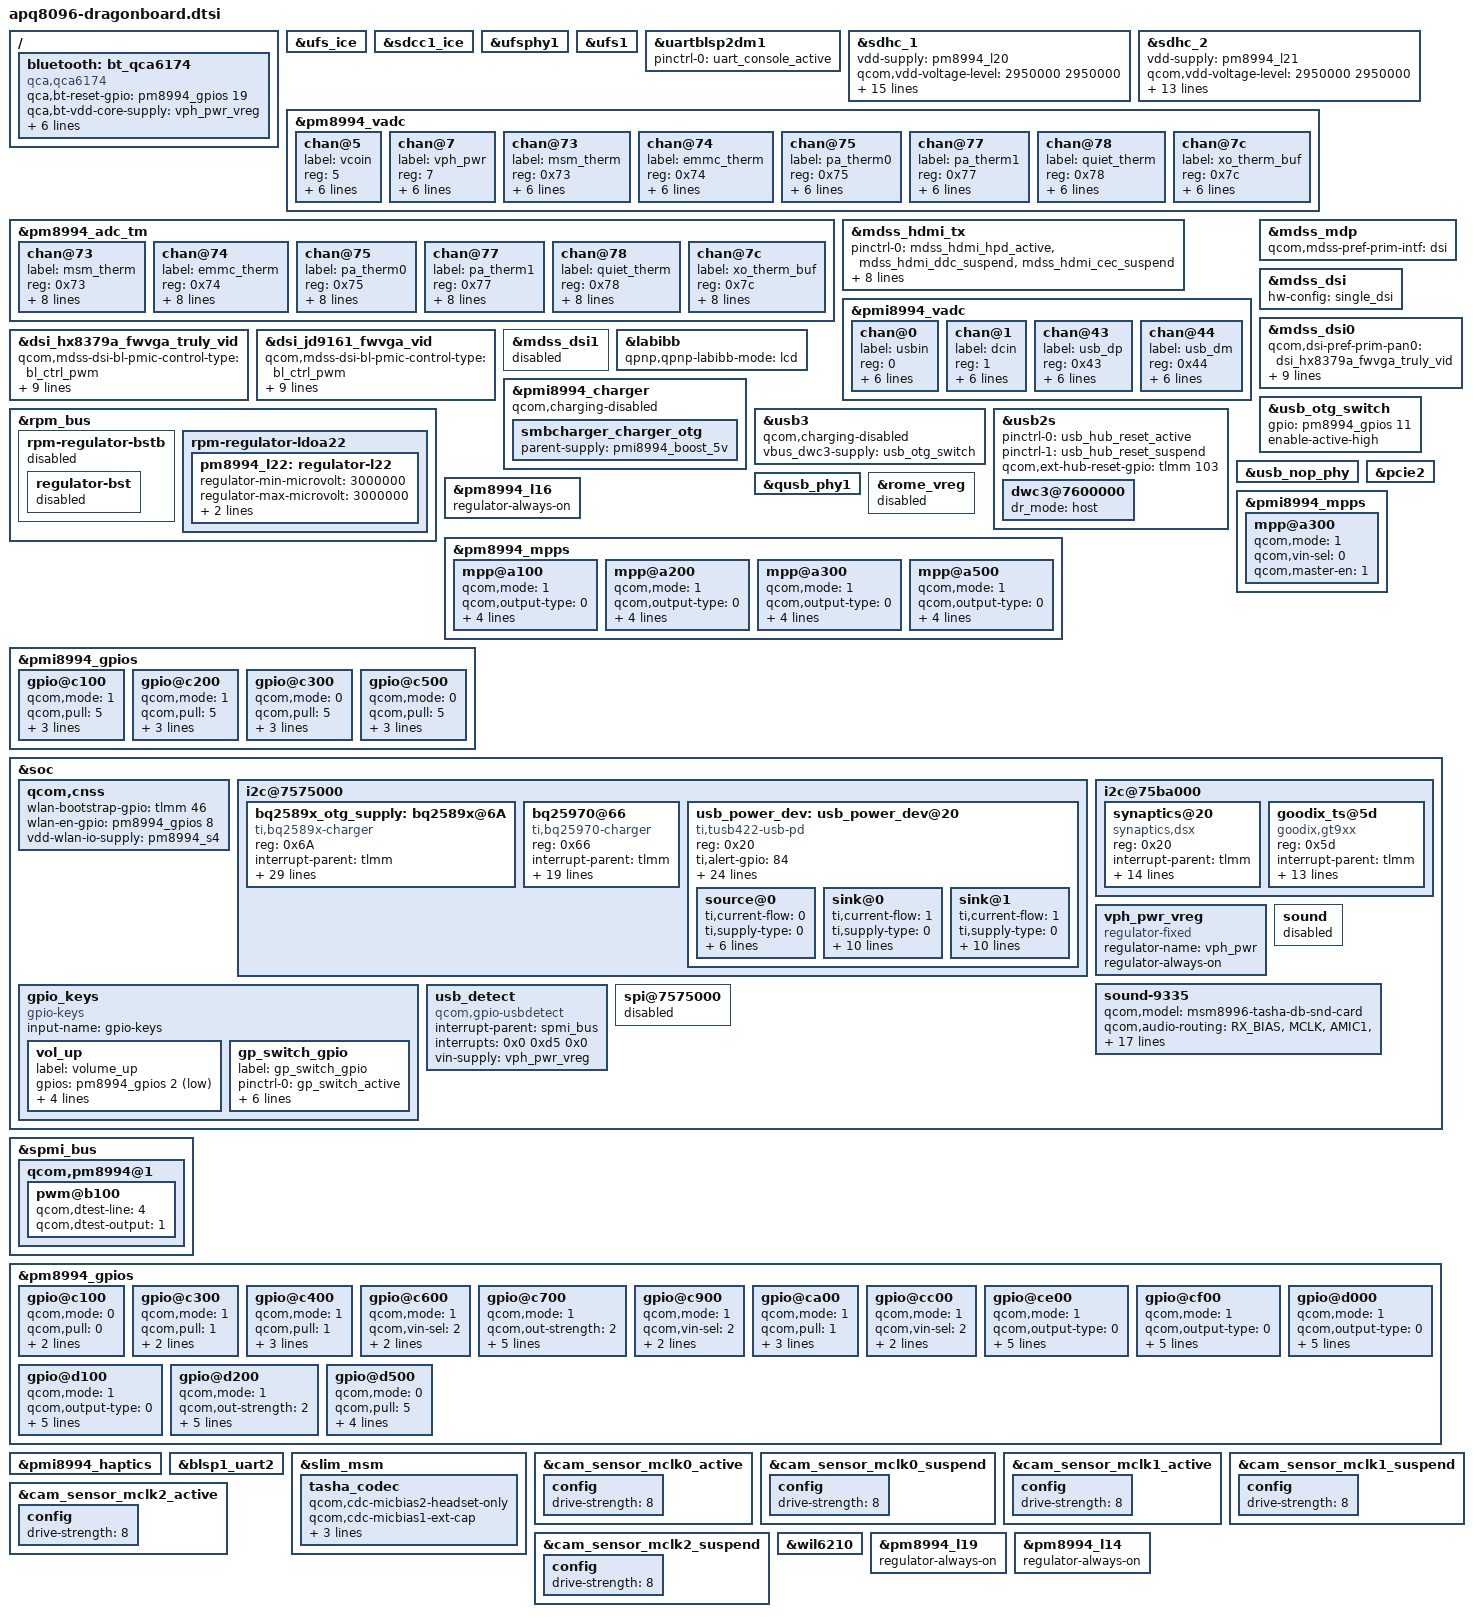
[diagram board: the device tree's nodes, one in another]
/* Copyright (c) 2015-2016, The Linux Foundation. All rights reserved.
 *
 * This program is free software; you can redistribute it and/or modify
 * it under the terms of the GNU General Public License version 2 and
 * only version 2 as published by the Free Software Foundation.
 *
 * This program is distributed in the hope that it will be useful,
 * but WITHOUT ANY WARRANTY; without even the implied warranty of
 * MERCHANTABILITY or FITNESS FOR A PARTICULAR PURPOSE.  See the
 * GNU General Public License for more details.
 */

#include "msm8996-pinctrl.dtsi"
#include "apq8096-camera-sensor-dragonboard.dtsi"

/ {
	bluetooth: bt_qca6174 {
		compatible = "qca,qca6174";
		qca,bt-reset-gpio = <&pm8994_gpios 19 0>; /* BT_EN */
		qca,bt-vdd-core-supply = <&vph_pwr_vreg>;
		qca,bt-vdd-pa-supply = <&vph_pwr_vreg>;
		qca,bt-vdd-io-supply = <&pm8994_s4>;
		qca,bt-vdd-xtal-supply = <&vph_pwr_vreg>;
		qca,bt-chip-pwd-voltage-level = <1300000 1300000>;
		qca,bt-vdd-io-voltage-level = <1800000 1800000>;
		qca,bt-vdd-xtal-voltage-level = <1800000 1800000>;
	};
};

&ufs_ice {
	status = "ok";
};

&sdcc1_ice {
	status = "ok";
};

&ufsphy1 {
	status = "ok";
};

&ufs1 {
	status = "ok";
};

&uartblsp2dm1 {
	status = "ok";
	pinctrl-names = "default";
	pinctrl-0 = <&uart_console_active>;
};

&sdhc_1 {
	vdd-supply = <&pm8994_l20>;
	qcom,vdd-voltage-level = <2950000 2950000>;
	qcom,vdd-current-level = <200 570000>;

	vdd-io-supply = <&pm8994_s4>;
	qcom,vdd-io-always-on;
	qcom,vdd-io-voltage-level = <1800000 1800000>;
	qcom,vdd-io-current-level = <110 325000>;

	pinctrl-names = "active", "sleep";
	pinctrl-0 = <&sdc1_clk_on &sdc1_cmd_on &sdc1_data_on &sdc1_rclk_on>;
	pinctrl-1 = <&sdc1_clk_off &sdc1_cmd_off &sdc1_data_off &sdc1_rclk_off>;

	qcom,clk-rates = <400000 20000000 25000000 50000000
				96000000 192000000 384000000>;
	qcom,ice-clk-rates = <300000000 150000000>;
	qcom,nonremovable;
	qcom,bus-speed-mode = "HS400_1p8v", "HS200_1p8v", "DDR_1p8v";

	status = "ok";
};

&sdhc_2 {
	vdd-supply = <&pm8994_l21>;
	qcom,vdd-voltage-level = <2950000 2950000>;
	qcom,vdd-current-level = <200 800000>;

	vdd-io-supply = <&pm8994_l13>;
	qcom,vdd-io-voltage-level = <1800000 2950000>;
	qcom,vdd-io-current-level = <200 22000>;

	pinctrl-names = "active", "sleep";
	pinctrl-0 = <&sdc2_clk_on  &sdc2_cmd_on &sdc2_data_on &sdc2_cd_on>;
	pinctrl-1 = <&sdc2_clk_off &sdc2_cmd_off &sdc2_data_off &sdc2_cd_off>;

	qcom,clk-rates = <400000 20000000 25000000 50000000
				100000000 200000000>;
	qcom,bus-speed-mode = "SDR12", "SDR25", "SDR50", "DDR50", "SDR104";

	cd-gpios = <&tlmm 95 0x1>;

	status = "ok";
};

&pm8994_vadc {
	chan@5 {
		label = "vcoin";
		reg = <5>;
		qcom,decimation = <0>;
		qcom,pre-div-channel-scaling = <1>;
		qcom,calibration-type = "absolute";
		qcom,scale-function = <0>;
		qcom,hw-settle-time = <0>;
		qcom,fast-avg-setup = <0>;
	};

	chan@7 {
		label = "vph_pwr";
		reg = <7>;
		qcom,decimation = <0>;
		qcom,pre-div-channel-scaling = <1>;
		qcom,calibration-type = "absolute";
		qcom,scale-function = <0>;
		qcom,hw-settle-time = <0>;
		qcom,fast-avg-setup = <0>;
	};

	chan@73 {
		label = "msm_therm";
		reg = <0x73>;
		qcom,decimation = <0>;
		qcom,pre-div-channel-scaling = <0>;
		qcom,calibration-type = "ratiometric";
		qcom,scale-function = <2>;
		qcom,hw-settle-time = <2>;
		qcom,fast-avg-setup = <0>;
	};

	chan@74 {
		label = "emmc_therm";
		reg = <0x74>;
		qcom,decimation = <0>;
		qcom,pre-div-channel-scaling = <0>;
		qcom,calibration-type = "ratiometric";
		qcom,scale-function = <2>;
		qcom,hw-settle-time = <2>;
		qcom,fast-avg-setup = <0>;
	};

	chan@75 {
		label = "pa_therm0";
		reg = <0x75>;
		qcom,decimation = <0>;
		qcom,pre-div-channel-scaling = <0>;
		qcom,calibration-type = "ratiometric";
		qcom,scale-function = <2>;
		qcom,hw-settle-time = <2>;
		qcom,fast-avg-setup = <0>;
	};

	chan@77 {
		label = "pa_therm1";
		reg = <0x77>;
		qcom,decimation = <0>;
		qcom,pre-div-channel-scaling = <0>;
		qcom,calibration-type = "ratiometric";
		qcom,scale-function = <2>;
		qcom,hw-settle-time = <2>;
		qcom,fast-avg-setup = <0>;
	};

	chan@78 {
		label = "quiet_therm";
		reg = <0x78>;
		qcom,decimation = <0>;
		qcom,pre-div-channel-scaling = <0>;
		qcom,calibration-type = "ratiometric";
		qcom,scale-function = <2>;
		qcom,hw-settle-time = <2>;
		qcom,fast-avg-setup = <0>;
	};

	chan@7c {
		label = "xo_therm_buf";
		reg = <0x7c>;
		qcom,decimation = <0>;
		qcom,pre-div-channel-scaling = <0>;
		qcom,calibration-type = "ratiometric";
		qcom,scale-function = <4>;
		qcom,hw-settle-time = <2>;
		qcom,fast-avg-setup = <0>;
	};
};

&pm8994_adc_tm {
	chan@73 {
		label = "msm_therm";
		reg = <0x73>;
		qcom,decimation = <0>;
		qcom,pre-div-channel-scaling = <0>;
		qcom,calibration-type = "ratiometric";
		qcom,scale-function = <2>;
		qcom,hw-settle-time = <2>;
		qcom,fast-avg-setup = <0>;
		qcom,btm-channel-number = <0x48>;
		qcom,thermal-node;
	};

	chan@74 {
		label = "emmc_therm";
		reg = <0x74>;
		qcom,decimation = <0>;
		qcom,pre-div-channel-scaling = <0>;
		qcom,calibration-type = "ratiometric";
		qcom,scale-function = <2>;
		qcom,hw-settle-time = <2>;
		qcom,fast-avg-setup = <0>;
		qcom,btm-channel-number = <0x68>;
		qcom,thermal-node;
	};

	chan@75 {
		label = "pa_therm0";
		reg = <0x75>;
		qcom,decimation = <0>;
		qcom,pre-div-channel-scaling = <0>;
		qcom,calibration-type = "ratiometric";
		qcom,scale-function = <2>;
		qcom,hw-settle-time = <2>;
		qcom,fast-avg-setup = <0>;
		qcom,btm-channel-number = <0x70>;
		qcom,thermal-node;
	};

	chan@77 {
		label = "pa_therm1";
		reg = <0x77>;
		qcom,decimation = <0>;
		qcom,pre-div-channel-scaling = <0>;
		qcom,calibration-type = "ratiometric";
		qcom,scale-function = <2>;
		qcom,hw-settle-time = <2>;
		qcom,fast-avg-setup = <0>;
		qcom,btm-channel-number = <0x78>;
		qcom,thermal-node;
	};

	chan@78 {
		label = "quiet_therm";
		reg = <0x78>;
		qcom,decimation = <0>;
		qcom,pre-div-channel-scaling = <0>;
		qcom,calibration-type = "ratiometric";
		qcom,scale-function = <2>;
		qcom,hw-settle-time = <2>;
		qcom,fast-avg-setup = <0>;
		qcom,btm-channel-number = <0x80>;
		qcom,thermal-node;
	};

	chan@7c {
		label = "xo_therm_buf";
		reg = <0x7c>;
		qcom,decimation = <0>;
		qcom,pre-div-channel-scaling = <0>;
		qcom,calibration-type = "ratiometric";
		qcom,scale-function = <4>;
		qcom,hw-settle-time = <2>;
		qcom,fast-avg-setup = <0>;
		qcom,btm-channel-number = <0x88>;
		qcom,thermal-node;
	};
};

&mdss_hdmi_tx {
	pinctrl-names = "hdmi_hpd_active", "hdmi_ddc_active", "hdmi_cec_active",
				"hdmi_active", "hdmi_sleep";
	pinctrl-0 = <&mdss_hdmi_hpd_active &mdss_hdmi_ddc_suspend
						&mdss_hdmi_cec_suspend>;
	pinctrl-1 = <&mdss_hdmi_hpd_active &mdss_hdmi_ddc_active
						&mdss_hdmi_cec_suspend>;
	pinctrl-2 = <&mdss_hdmi_hpd_active &mdss_hdmi_cec_active
						&mdss_hdmi_ddc_suspend>;
	pinctrl-3 = <&mdss_hdmi_hpd_active &mdss_hdmi_ddc_active
						&mdss_hdmi_cec_active>;
	pinctrl-4 = <&mdss_hdmi_hpd_suspend &mdss_hdmi_ddc_suspend
						&mdss_hdmi_cec_suspend>;
};

&pmi8994_vadc {
	chan@0 {
		label = "usbin";
		reg = <0>;
		qcom,decimation = <0>;
		qcom,pre-div-channel-scaling = <4>;
		qcom,calibration-type = "absolute";
		qcom,scale-function = <0>;
		qcom,hw-settle-time = <0>;
		qcom,fast-avg-setup = <0>;
	};

	chan@1 {
		label = "dcin";
		reg = <1>;
		qcom,decimation = <0>;
		qcom,pre-div-channel-scaling = <4>;
		qcom,calibration-type = "absolute";
		qcom,scale-function = <0>;
		qcom,hw-settle-time = <0>;
		qcom,fast-avg-setup = <0>;
	};

	chan@43 {
		label = "usb_dp";
		reg = <0x43>;
		qcom,decimation = <0>;
		qcom,pre-div-channel-scaling = <1>;
		qcom,calibration-type = "absolute";
		qcom,scale-function = <0>;
		qcom,hw-settle-time = <0>;
		qcom,fast-avg-setup = <0>;
	};

	chan@44 {
		label = "usb_dm";
		reg = <0x44>;
		qcom,decimation = <0>;
		qcom,pre-div-channel-scaling = <1>;
		qcom,calibration-type = "absolute";
		qcom,scale-function = <0>;
		qcom,hw-settle-time = <0>;
		qcom,fast-avg-setup = <0>;
	};
};

#include "msm8996-mdss-panels.dtsi"

&dsi_hx8379a_fwvga_truly_vid {
	qcom,mdss-dsi-bl-pmic-control-type = "bl_ctrl_pwm";
	qcom,mdss-dsi-bl-min-level = <1>;
	qcom,mdss-dsi-bl-max-level = <255>;
	qcom,mdss-dsi-bl-pmic-pwm-frequency = <50>;
	qcom,mdss-dsi-bl-pmic-bank-select = <0>;
	qcom,mdss-dsi-pwm-gpio = <&pm8994_gpios 5 0>;
	qcom,panel-supply-entries = <&dsi_panel_pwr_supply>;
	qcom,suspend-ulps-enabled;
	qcom,ulps-enabled;
};

&dsi_jd9161_fwvga_vid {
	qcom,mdss-dsi-bl-pmic-control-type = "bl_ctrl_pwm";
	qcom,mdss-dsi-bl-min-level = <1>;
	qcom,mdss-dsi-bl-max-level = <255>;
	qcom,mdss-dsi-bl-pmic-pwm-frequency = <50>;
	qcom,mdss-dsi-bl-pmic-bank-select = <0>;
	qcom,mdss-dsi-pwm-gpio = <&pm8994_gpios 5 0>;
	qcom,panel-supply-entries = <&dsi_panel_pwr_supply>;
	qcom,suspend-ulps-enabled;
	qcom,ulps-enabled;
};

&mdss_mdp {
	qcom,mdss-pref-prim-intf = "dsi";
};

&mdss_dsi {
	hw-config = "single_dsi";
};

&mdss_dsi0 {
	qcom,dsi-pref-prim-pan0 = <&dsi_hx8379a_fwvga_truly_vid>;
	qcom,dsi-pref-prim-pan1 = <&dsi_jd9161_fwvga_vid>;
	pinctrl-names = "mdss_default", "mdss_sleep";
	pinctrl-0 = <&mdss_dsi_active &mdss_te_active &mdss_disp_bkl_active>;
	pinctrl-1 = <&mdss_dsi_suspend &mdss_te_suspend &mdss_disp_bkl_suspend>;
	qcom,platform-te-gpio = <&tlmm 10 0>;
	qcom,platform-reset-gpio = <&tlmm 8 0>;
	qcom,platform-bklight-en-gpio = <&tlmm 135 0>;
	qcom,panel-ident-gpio = <&tlmm 81 0x00>;
};

&mdss_dsi1 {
	status = "disabled";
};

&labibb {
	status = "ok";
	qpnp,qpnp-labibb-mode = "lcd";
};

&rpm_bus {
	rpm-regulator-bstb {
		status = "disabled";
		regulator-bst {
			status = "disabled";
		};
	};

	rpm-regulator-ldoa22 {
		pm8994_l22: regulator-l22 {
			regulator-min-microvolt = <3000000>;
			regulator-max-microvolt = <3000000>;
			qcom,init-voltage = <3000000>;
		};
	};
};

&pmi8994_charger {
	/delete-property/ otg-parent-supply;
	qcom,charging-disabled;
	smbcharger_charger_otg {
		parent-supply = <&pmi8994_boost_5v>;
	};
};

&usb_otg_switch {
	/delete-property/ vin-supply;
	gpio = <&pm8994_gpios 11 0>;
	enable-active-high;
	status = "ok";
};

&usb3 {
	qcom,charging-disabled;
	vbus_dwc3-supply = <&usb_otg_switch>;
};

&usb2s {
	status = "ok";
	pinctrl-0 = <&usb_hub_reset_active>;
	pinctrl-1 = <&usb_hub_reset_suspend>;
	qcom,ext-hub-reset-gpio =  <&tlmm 103 0>;
	dwc3@7600000 {
		dr_mode = "host";
	};
};

&usb_nop_phy {
	status = "ok";
};

&qusb_phy1 {
	status = "ok";
};

&rome_vreg {
	status = "disabled";
};

&pm8994_l16 { /* GPS ELNA */
	status = "okay";
	regulator-always-on;
};

&pcie2 {
    /delete-property/ qcom,ep-wakeirq;
    /delete-property/ qcom,msi-gicm-addr;
    /delete-property/ qcom,msi-gicm-base;
};

&pm8994_mpps {
	mpp@a100 { /* MPP 2 */
		qcom,mode = <1>;		/* Digital output */
		qcom,output-type = <0>;		/* CMOS logic */
		qcom,vin-sel = <2>;		/* S4 1.8V */
		qcom,src-sel = <0>;		/* Constant */
		qcom,master-en = <1>;		/* Enable GPIO */
		qcom,invert = <0>;
		status = "okay";
	};

	mpp@a200 { /* MPP 3 */
		qcom,mode = <1>;		/* Digital output */
		qcom,output-type = <0>;		/* CMOS logic */
		qcom,vin-sel = <2>;		/* S4 1.8V */
		qcom,src-sel = <0>;		/* Constant */
		qcom,master-en = <1>;		/* Enable GPIO */
		qcom,invert = <0>;
		status = "okay";
	};

	mpp@a300 { /* MPP 4 */
		/* HDMI_5v_vreg regulator enable */
		qcom,mode = <1>;		/* Digital output */
		qcom,output-type = <0>;		/* CMOS logic */
		qcom,vin-sel = <2>;		/* S4 1.8V */
		qcom,src-sel = <0>;		/* Constant */
		qcom,master-en = <1>;		/* Enable GPIO */
		qcom,invert = <0>;
		status = "okay";
	};

	mpp@a500 { /* MPP 6 */
		qcom,mode = <1>;		/* Digital output */
		qcom,output-type = <0>;		/* CMOS logic */
		qcom,vin-sel = <2>;		/* S4 1.8V */
		qcom,src-sel = <0>;		/* Constant */
		qcom,master-en = <1>;		/* Enable GPIO */
		qcom,invert = <0>;
		status = "okay";
	};
};


&pmi8994_gpios {
	gpio@c100 {	/* GPIO 2  SPKR_SD_N */
		qcom,mode = <1>;	/* DIGITAL OUT */
		qcom,pull = <5>;	/* No Pull */
		qcom,vin-sel = <2>;	/* 1.8 */
		qcom,src-sel = <0>;	/* CONSTANT */
		qcom,master-en = <1>;	/* ENABLE GPIO */
		status = "okay";
	};

	gpio@c200 {	/* GPIO 3 SPKR_SD_N */
		qcom,mode = <1>;	/* DIGITAL OUT */
		qcom,pull = <5>;	/* No Pull */
		qcom,vin-sel = <2>;	/* 1.8 */
		qcom,src-sel = <0>;	/* CONSTANT */
		qcom,master-en = <1>;	/* ENABLE GPIO */
		status = "okay";
	};

	gpio@c300 {	/* GPIO 4 USB2_ID */
		qcom,mode = <0>;	/* DIGITAL INPUT */
		qcom,pull = <5>;	/* No Pull */
		qcom,vin-sel = <2>;	/* 1.8 */
		qcom,src-sel = <0>;	/* CONSTANT */
		qcom,master-en = <1>;	/* ENABLE GPIO */
		status = "okay";
	};

	gpio@c500 {	/* GPIO 6 USB2_VBUS_DET*/
		qcom,mode = <0>;	/* DIGITAL INPUT */
		qcom,pull = <5>;	/* No Pull */
		qcom,vin-sel = <2>;	/* 1.8 */
		qcom,src-sel = <0>;	/* CONSTANT */
		qcom,master-en = <1>;	/* ENABLE GPIO */
		status = "okay";
	};
};

&pmi8994_mpps {
	mpp@a300 { /* MPP 4 */
		/* WLED FET */
		qcom,mode = <1>;        /* DIGITAL OUT */
		qcom,vin-sel = <0>;     /* VIN0 */
		qcom,master-en = <1>;
		status = "okay";
	};
};

&soc {
	qcom,cnss {
		wlan-bootstrap-gpio = <&tlmm 46 0>;
		wlan-en-gpio = <&pm8994_gpios 8 0>;
		vdd-wlan-io-supply = <&pm8994_s4>;
		// removing unneeded regulators
		/delete-property/ vdd-wlan-supply;
		/delete-property/ vdd-wlan-xtal-supply;
		/delete-property/ vdd-wlan-core-supply;
	};

	i2c@7575000 {
	bq2589x_otg_supply: bq2589x@6A {
			compatible = "ti,bq2589x-charger";
			reg = <0x6A>;
			interrupt-parent = <&tlmm>;
			interrupts = <0 2>;
			pinctrl-names = "default";
			pinctrl-0 = <&bq2589x_int_default>;

			regulator-name = "bq2589x_otg_vreg";
			    
			ti,bq2589x,dpdm-switch-gpio = <141>;
					
			ti,bq2589x,enable-auto-dpdm;
			ti,bq2589x,enable-termination;
			ti,bq2589x,enable-ico;
			ti,bq2589x,use-absolute-vindpm;
			ti,bq2589x,enable-12v;
			ti,bq2589x,enable-hvdcp;
					
			ti,bq2589x,charge-voltage = <4200>;
			ti,bq2589x,charge-current = <2000>;

			ti,bq2589x,precharge-current = <256>;
			ti,bq2589x,termination-current = <60>;
			ti,bq2589x,boost-voltage = <4998>;
			ti,bq2589x,boost-current = <1200>;
			ti,bq2589x,enable_term;

			ti,bq2589x,jeita-hot-degc = <540>;
			ti,bq2589x,jeita-warm-degc = <450>;
			ti,bq2589x,jeita-cool-degc = <150>;
			ti,bq2589x,jeita-cold-degc = <0>;

			ti,bq2589x,jeita-hot-hysteresis = <10>;
			ti,bq2589x,jeita-cold-hysteresis = <0>;

			ti,bq2589x,jeita-cool-ma = <900>;
			ti,bq2589x,jeita-cool-mv = <4400>;
			ti,bq2589x,jeita-warm-ma = <900>;
			ti,bq2589x,jeita-warm-mv = <4112>;

			ti,bq2589x,software-jeita-supported;

			ti,thermal-mitigation = <1000 800 600 0>;
		};
		bq25970@66 {
			compatible = "ti,bq25970-charger";
			reg = <0x66>;
			interrupt-parent = <&tlmm>;
			interrupts = <1 2>;
			pinctrl-names = "default";
			pinctrl-0 = <&bq2597x_int_default>;

		/*	ti,bq2597x,bat-ovp-disable;	*/
			ti,bq2597x,bat-ovp-alarm-disable;	
		/*	ti,bq2597x,bat-ocp-disable;	
			ti,bq2597x,bat-ocp-alarm-disable; */
			
		/*	ti,bq2597x,bat-ucp-disable;	*/

		/*	ti,bq2597x,bus-ovp-alarm-disable;	
			ti,bq2597x,bus-ocp-disable;	
			ti,bq2597x,bus-ocp-alarm-disable;	

		*/			
			ti,bq2597x,bat-therm-disable;	
			ti,bq2597x,bus-therm-disable;	
			ti,bq2597x,die-therm-disable;	

			ti,bq2597x,bat-ovp-threshold = <4350>;
			ti,bq2597x,bat-ovp-alarm-threshold = <4200>;
			ti,bq2597x,bat-ocp-threshold = <8100>;
			ti,bq2597x,bat-ocp-alarm-threshold = <8000>;

			ti,bq2597x,bus-ovp-threshold = <8900>;
			ti,bq2597x,bus-ovp-alarm-threshold = <8800>;
			ti,bq2597x,bus-ocp-threshold = <4250>;
			ti,bq2597x,bus-ocp-alarm-threshold = <4000>;

			ti,bq2597x,bat-ucp-alarm-threshold = <2000>;

			ti,bq2597x,bat-therm-threshold = <0x15>;/*4.1%*/
			ti,bq2597x,bus-therm-threshold = <0x15>;/*4.1%*/
			ti,bq2597x,die-therm-threshold = <125>;

			ti,bq2597x,ac-ovp-threshold = <11>;
		};


		usb_power_dev: usb_power_dev@20 {
			compatible = "ti,tusb422-usb-pd";
			reg = <0x20>;
			/* Config for TUSB422 EVM GPIOs */
/*			interrupt-parent = <&tlmm>;
			interrupts = <84 2>;
			pinctrl-names = "default";
			pinctrl-0 = <&tusb422_int_default>;
*/

			ti,alert-gpio = <84>;
/*
			ti,alert-gpio = <&gpio1 16 GPIO_ACTIVE_HIGH>;
			ti,vbus-snk-gpio = <&gpio1 28 GPIO_ACTIVE_HIGH>;
			ti,vbus-src-gpio = <&gpio3 21 GPIO_ACTIVE_HIGH>;
			ti,vconn-en-gpio = <&gpio3 19 GPIO_ACTIVE_HIGH>;
			ti,vbus-hv-gpio = <&gpio1 17 GPIO_ACTIVE_HIGH>;
			ti,vbus-5v-gpio = <&gpio0 7 GPIO_ACTIVE_HIGH>;
*/
			/* Port Config */
			/*ti,usb-comm-capable;*/
			ti,no-usb-suspend;
			ti,externally-powered;
			/* Uncomment the below tags to make them true for the driver
			 * otherwise they are false */
			/* ti,usb-suspend-supported;
			ti,externally-powered;
			ti,dual-role-data;
			ti,higher-capability;
			ti,giveback-flag; */
			/*ti,auto-accept-swap-to-dfp;*/
			ti,auto-accept-swap-to-ufp;
			/*ti,auto-accept-swap-to-source;*/
			ti,auto-accept-swap-to-sink;
			/*ti,auto-accept-vconn-swap;*/

			ti,src-settling-time-ms = <50>;
			ti,fast-role-swap-support = <0>;
			ti,pdo-priority = <0>;
			ti,role = <1>;    /* 0 = SRC, 1 = SNK, 2 = DRP */
			ti,rp-val = <2>;  /* 0 = default, 1 = 1.5A, 2 = 3.0A */
			ti,flags = <2>;   /* 0 = none, 1 = Try.SRC, 2 = Try.SNK */

			/* Config for VDM with DisplayPort Alt-Mode Host support */
			/*ti,ufp-alt-mode-entry-timeout-enable;*/
			/*ti,multi-function-preferred;*/
			ti,id-header-vdo = <0xD5000451>; /* 0xD500xxxx = USB Host and Device communication capable and modal operation supported */ 
			ti,cert-stat-vdo = <0x0>;
			ti,product-vdo = <0x92610000>;
			ti,num-product-type-vdos = <0>;
			ti,product-type-vdo-1 = <0>;
			ti,product-type-vdo-2 = <0>;
			ti,product-type-vdo-3 = <0>;
			ti,num-svids = <1>;
			ti,svid-1 = <0xFF01>; /* 0xFF01 = DisplayPort. ENABLE_DP_ALT_MODE_SUPPORT must be defined in usb_pd_policy_engine.h to support this SVID */
			ti,svid-2 = <0>;
			ti,svid-3 = <0>;
			ti,mode-1 = <0x1C46>; /* 0x1C46 = DFP_D, DP_v1.3, receptacle, USB 2 signaling may be required, DFP_D pin assignment C, D, E */
			ti,mode-2 = <0>;
			ti,mode-3 = <0>;

			source@0 {
				ti,current-flow = <0>; /* 0 for source, 1 for sink */
				ti,supply-type = <0>;
				ti,pdo-number = <0>;
				ti,min-voltage = <5000>;
				ti,max-voltage = <0>;
				ti,peak-current = <0>;
				ti,max-current = <3000>;
				ti,max-power = <0>;
			};

			sink@0 {
				ti,current-flow = <1>; /* 0 for source, 1 for sink */
				ti,supply-type = <0>;
				ti,pdo-number = <0>;
				ti,min-voltage = <5000>;
				ti,max-voltage = <0>;
				ti,max-operating-curr = <2000>;
				ti,min-operating-curr = <100>;
				ti,operational-curr = <2000>;
				ti,max-operating-pwr = <0>;
				ti,min-operating-pwr = <0>;
				ti,operational-pwr = <0>;
				ti,peak-current = <0>;
			};

			sink@1 {
				ti,current-flow = <1>; /* 0 for source, 1 for sink */
				ti,supply-type = <0>;
				ti,pdo-number = <1>;
				ti,min-voltage = <9000>;
				ti,max-voltage = <0>;
				ti,max-operating-curr = <2000>;
				ti,min-operating-curr = <100>;
				ti,operational-curr = <2000>;
				ti,max-operating-pwr = <0>;
				ti,min-operating-pwr = <0>;
				ti,operational-pwr = <0>;
				ti,peak-current = <0>;
			};
		};
	};

	i2c@75ba000 {
		synaptics@20 {
			compatible = "synaptics,dsx";
			reg = <0x20>;
			interrupt-parent = <&tlmm>;
			interrupts = <125 0x2008>;
			vdd-supply = <&pm8994_l14>;
			avdd-supply = <&pm8994_l22>;
			pinctrl-names = "pmx_ts_active", "pmx_ts_suspend";
			pinctrl-0 = <&ts_active>;
			pinctrl-1 = <&ts_suspend>;
			synaptics,display-coords = <0 0 480 854>;
			synaptics,panel-coords = <0 0 480 854>;
			synaptics,touch-ident-gpio = <&tlmm 81 0x00>;
			synaptics,reset-gpio = <&tlmm 89 0x00>;
			synaptics,irq-gpio = <&tlmm 125 0x2008>;
			synaptics,button-map = <139 102 158>;
			synaptics,disable-gpios;
			/* Underlying clocks used by secure touch */
			clock-names = "iface_clk", "core_clk";
			clocks = <&clock_gcc clk_gcc_blsp2_ahb_clk>,
				 <&clock_gcc clk_gcc_blsp2_qup6_i2c_apps_clk>;
		};
		goodix_ts@5d {
			compatible = "goodix,gt9xx";
			reg = <0x5d>;
			interrupt-parent = <&tlmm>;
			interrupts = <125 0x2008>;
			vdd_ana-supply = <&pm8994_l22>;
			pinctrl-names = "pmx_ts_active", "pmx_ts_suspend";
			pinctrl-0 = <&ts_active>;
			pinctrl-1 = <&ts_suspend>;
			goodix,touch-ident-gpio = <&tlmm 81 0x00>;
			goodix,rst-gpio = <&tlmm 89 0x00>;
			goodix,irq-gpio = <&tlmm 125 0x00>;
			clock-names = "iface_clk", "core_clk";
			clocks = <&clock_gcc clk_gcc_blsp2_ahb_clk>,
			       <&clock_gcc clk_gcc_blsp2_qup6_i2c_apps_clk>;
			goodix,cfg-group0 = [
				42 D0 02 00 05 05 75 01 01 0F 24
				0F 64 3C 03 05 00 00 00 02 00 00
				00 16 19 1C 14 8C 0E 0E 24 00 31
				0D 00 00 00 83 33 1D 00 41 00 00
				00 00 00 08 0A 00 2B 1C 3C 94 D5
				03 08 00 00 04 93 1E 00 82 23 00
				74 29 00 69 2F 00 5F 37 00 5F 20
				40 60 00 F0 40 30 55 50 27 00 00
				00 00 00 00 00 00 00 00 00 00 00
				00 00 00 00 00 00 00 14 19 00 00
				50 50 02 04 06 08 0A 0C 0E 10 12
				14 16 18 1A 1C 00 00 00 00 00 00
				00 00 00 00 00 00 00 00 00 00 1D
				1E 1F 20 21 22 24 26 28 29 2A 1C
				18 16 14 13 12 10 0F 0C 0A 08 06
				04 02 00 00 00 00 00 00 00 00 00
				00 00 00 00 00 00 00 00 9C 01];
			goodix,cfg-group2 = [
				5A E0 01 56 03 0A 05 01 01 0F 23
				0F 50 32 03 05 00 00 FF 7F 01 00
				0F 18 1A 1E 14 89 29 0A 59 5B 09
				06 03 0A 00 02 32 11 55 01 00 00
				00 00 00 32 00 00 2B 2D 67 94 C5
				02 07 00 00 04 DD 31 00 C0 39 00
				A3 44 00 8C 50 00 78 5F 00 78 00
				00 00 00 F0 4A 3A FF FF 27 00 1E
				02 32 1E 02 05 2D 1E 19 00 00 01
				0F 0F 03 04 10 42 F8 0F 19 00 00
				46 32 08 0A 0C 0E 10 12 14 16 18
				1A 00 00 00 00 00 00 00 00 00 00
				00 00 00 00 FF FF FF FF 00 00 2A
				29 28 24 22 20 1F 1E 1D 0E 0C 0A
				08 06 05 04 02 00 00 00 00 00 00
				00 00 00 00 FF FF FF FF FF FF FF
				FF FF FF FF FF FF FF FF 74 01];
		};
	};

	gpio_keys {
		compatible = "gpio-keys";
		input-name = "gpio-keys";

		vol_up {
			label = "volume_up";
			gpios = <&pm8994_gpios 2 0x1>;
			linux,input-type = <1>;
			linux,code = <115>;
			gpio-key,wakeup;
			debounce-interval = <15>;
		};


		gp_switch_gpio {
			label = "gp_switch_gpio";
			pinctrl-0 = <&gp_switch_active>;
			pinctrl-1 = <&gp_switch_suspend>;
			gpios = <&tlmm 127 0x1>;
			linux,input-type = <1>;
			linux,code = <158>; /* By default mapped to BACK */
			gpio-key,wakeup;
			debounce-interval = <15>;
		};
	};

	/*
	* vph_pwr_vreg represents the unregulated battery voltage supply
	* VPH_PWR that is present whenever the device is powered on.
	*/
	vph_pwr_vreg: vph_pwr_vreg {
		compatible = "regulator-fixed";
		regulator-name = "vph_pwr";
		status = "ok";
		regulator-always-on;
	};


	sound {
		status = "disabled";
	};

	sound-9335 {
		qcom,model = "msm8996-tasha-db-snd-card";

		qcom,audio-routing =
			"RX_BIAS", "MCLK",
			"AMIC1", "MIC BIAS3",
			"MIC BIAS3", "Analog Mic4",
			"AMIC2", "MIC BIAS2",
			"MIC BIAS2", "Headset Mic",
			"AMIC3", "MIC BIAS2",
			"MIC BIAS2", "ANCLeft Headset Mic",
			"AMIC4", "MIC BIAS2",
			"MIC BIAS2", "ANCRight Headset Mic",
			"AMIC5", "MIC BIAS3",
			"MIC BIAS3", "Analog Mic6",
			"AMIC6", "MIC BIAS4",
			"MIC BIAS4", "Analog Mic7",
			"DMIC0", "MIC BIAS1",
			"MIC BIAS1", "Digital Mic0",
			"DMIC1", "MIC BIAS3",
			"MIC BIAS3", "Digital Mic1",
			"DMIC2", "MIC BIAS4",
			"MIC BIAS4", "Digital Mic2",
			"DMIC3", "MIC BIAS1",
			"MIC BIAS1", "Digital Mic3",
			"DMIC4", "MIC BIAS3",
			"MIC BIAS3", "Digital Mic4",
			"DMIC5", "MIC BIAS4",
			"MIC BIAS4", "Digital Mic5";

		qcom,hdmi-audio-rx;
		asoc-codec = <&stub_codec>, <&hdmi_audio>;
		asoc-codec-names = "msm-stub-codec.1",
					"msm-hdmi-audio-codec-rx";
	};

	usb_detect {
		compatible = "qcom,gpio-usbdetect";
		interrupt-parent = <&spmi_bus>;
		interrupts = <0x0 0xd5 0x0>;  /* PM8994 GPIO22 */
		interrupt-names = "vbus_det_irq";
		vin-supply = <&vph_pwr_vreg>;
	};

	spi@7575000 { /* BLSP1 QUP1 */
		status = "disabled";
	};
};

&spmi_bus {
	qcom,pm8994@1 {
		pwm@b100 {
			qcom,dtest-line = <4>;
			qcom,dtest-output = <1>;
			status = "okay";
		};
	};
};

&pm8994_gpios {
	gpio@c100 { /* GPIO 2 - KYPD_VOLP_N */
		qcom,mode = <0>;
		qcom,pull = <0>;
		qcom,vin-sel = <2>;
		qcom,src-sel = <0>;
		status = "okay";
	};

	gpio@c300 { /* GPIO 4 - BL1_PWM */
		qcom,mode = <1>;
		qcom,pull = <1>;
		qcom,vin-sel = <2>;
		qcom,src-sel = <4>;
		status = "okay";
	};

	gpio@c400 { /* GPIO 5 - BL0_PWM */
		qcom,mode = <1>;	/* DIGITAL OUT */
		qcom,pull = <1>;	/* PULL DOWN */
		qcom,vin-sel = <2>;	/* 1.8 */
		qcom,src-sel = <7>;	/* LPG4 */
		qcom,master-en = <1>;   /* Enable GPIO */
		status = "okay";
	};

	gpio@c600 { /* GPIO 7 */
		qcom,mode = <1>;	/* DIGITAL OUT */
		qcom,vin-sel = <2>;	/* 1.8 */
		qcom,src-sel = <0>;	/* GPIO */
		qcom,master-en = <1>;	/* ENABLE GPIO */
		status = "okay";
	};

	gpio@c700 { /* GPIO 8 - WLAN_EN */
		qcom,mode = <1>;	/* Digital output*/
		qcom,out-strength = <2>;/* QPNP_PIN_OUT_STRENGTH_MED */
		qcom,pull = <4>;	/* Pulldown 10uA */
		qcom,vin-sel = <2>;	/* VIN2 */
		qcom,src-sel = <0>;	/* GPIO */
		qcom,invert = <0>;	/* Invert */
		qcom,master-en = <1>;	/* Enable GPIO */
		status = "okay";
	};

	gpio@c900 { /* GPIO 10 */
		qcom,mode = <1>;	/* DIGITAL OUT */
		qcom,vin-sel = <2>;	/* 1.8 */
		qcom,src-sel = <0>;	/* GPIO */
		qcom,master-en = <1>;	/* ENABLE GPIO */
		status = "okay";
	};

	gpio@ca00 { /* GPIO 11 - USB enb1 (otg switch) */
		qcom,mode = <1>;	/* DIGITAL OUT */
		qcom,pull = <1>;	/* PULL DOWN */
		qcom,vin-sel = <2>;	/* 1.8 */
		qcom,src-sel = <0>;	/* GPIO */
		qcom,master-en = <1>;	/* Enable GPIO */
		status = "okay";
	};

	gpio@cc00 { /* GPIO 13 */
		qcom,mode = <1>;	/* DIGITAL OUT */
		qcom,vin-sel = <2>;	/* 1.8 */
		qcom,src-sel = <0>;	/* GPIO */
		qcom,master-en = <1>;	/* Enable GPIO */
		status = "okay";
	};

	gpio@ce00 { /* GPIO 15 - DIVCLK1 */
		qcom,mode = <1>;
		qcom,output-type = <0>;
		qcom,pull = <5>;
		qcom,vin-sel = <2>;
		qcom,out-strength = <1>;
		qcom,src-sel = <2>;
		qcom,master-en = <1>;
		status = "okay";
	};

	gpio@cf00 { /* GPIO 16 - DIVCLK2 */
		qcom,mode = <1>;
		qcom,output-type = <0>;
		qcom,pull = <5>;
		qcom,vin-sel = <2>;
		qcom,out-strength = <1>;
		qcom,src-sel = <2>;
		qcom,master-en = <1>;
		status = "okay";
	};

	gpio@d000 { /* GPIO 17 - DIVCLK3 */
		qcom,mode = <1>;
		qcom,output-type = <0>;
		qcom,pull = <5>;
		qcom,vin-sel = <2>;
		qcom,out-strength = <1>;
		qcom,src-sel = <2>;
		qcom,master-en = <1>;
		status = "okay";
	};

	gpio@d100 { /* GPIO 18 - Rome Sleep Clock */
		qcom,mode = <1>;		/* Digital output */
		qcom,output-type = <0>;		/* CMOS logic */
		qcom,invert = <0>;		/* Output low initially */
		qcom,vin-sel = <2>;		/* VIN 2 */
		qcom,src-sel = <3>;		/* Function 2 */
		qcom,out-strength = <2>;	/* Medium */
		qcom,master-en = <1>;		/* Enable GPIO */
		status = "okay";
	};

	gpio@d200 { /* GPIO 19 - Rome BT Reset */
		qcom,mode = <1>;		/* Digital output*/
		qcom,out-strength = <2>;	/* QPNP_PIN_OUT_STRENGTH_MED */
		qcom,pull = <4>;		/* Pulldown 10uA */
		qcom,vin-sel = <2>;		/* VIN2 */
		qcom,src-sel = <0>;		/* GPIO */
		qcom,invert = <0>;		/* Invert */
		qcom,master-en = <1>;		/* Enable GPIO */
		status = "okay";
	};

	gpio@d500 { /* GPIO 22 - USB1 VBUS detect  */
		qcom,mode = <0>;		/* Digital Input*/
		qcom,pull = <5>;		/* No pull */
		qcom,vin-sel = <2>;		/* 1.8 V */
		qcom,src-sel = <0>;		/* GPIO */
		qcom,invert = <0>;		/* Invert */
		qcom,master-en = <1>;		/* Enable GPIO */
		status = "okay";
	};
};

&pmi8994_haptics {
	status = "okay";
};

&blsp1_uart2 {
	status = "ok";
};

&slim_msm {
	tasha_codec {
		qcom,cdc-micbias2-headset-only;
		qcom,cdc-micbias1-ext-cap;
		qcom,cdc-micbias2-ext-cap;
		qcom,cdc-micbias3-ext-cap;
		qcom,cdc-micbias4-ext-cap;
	};
};

&cam_sensor_mclk0_active { /* MCLK0 */
	config {
		drive-strength = <8>; /* 8 MA */
	};
};

&cam_sensor_mclk0_suspend { /* MCLK0 */
	config {
		drive-strength = <8>; /* 8 MA */
	};
};

&cam_sensor_mclk1_active { /* MCLK1 */
	config {
		drive-strength = <8>; /* 8 MA */
	};
};

&cam_sensor_mclk1_suspend { /* MCLK1 */
	config {
		drive-strength = <8>; /* 8 MA */
	};
};

&cam_sensor_mclk2_active { /* MCLK2 */
	config {
		drive-strength = <8>; /* 8 MA */
	};
};

&cam_sensor_mclk2_suspend { /* MCLK2 */
	config {
		drive-strength = <8>; /* 8 MA */
	};
};

&wil6210 {
	status = "ok";
	/delete-property/ qcom,wigig-en;
};

&pm8994_l19 {
	regulator-always-on;
};
&pm8994_l22 {
	regulator-always-on;
};
&pm8994_l14 {
	regulator-always-on;
};
